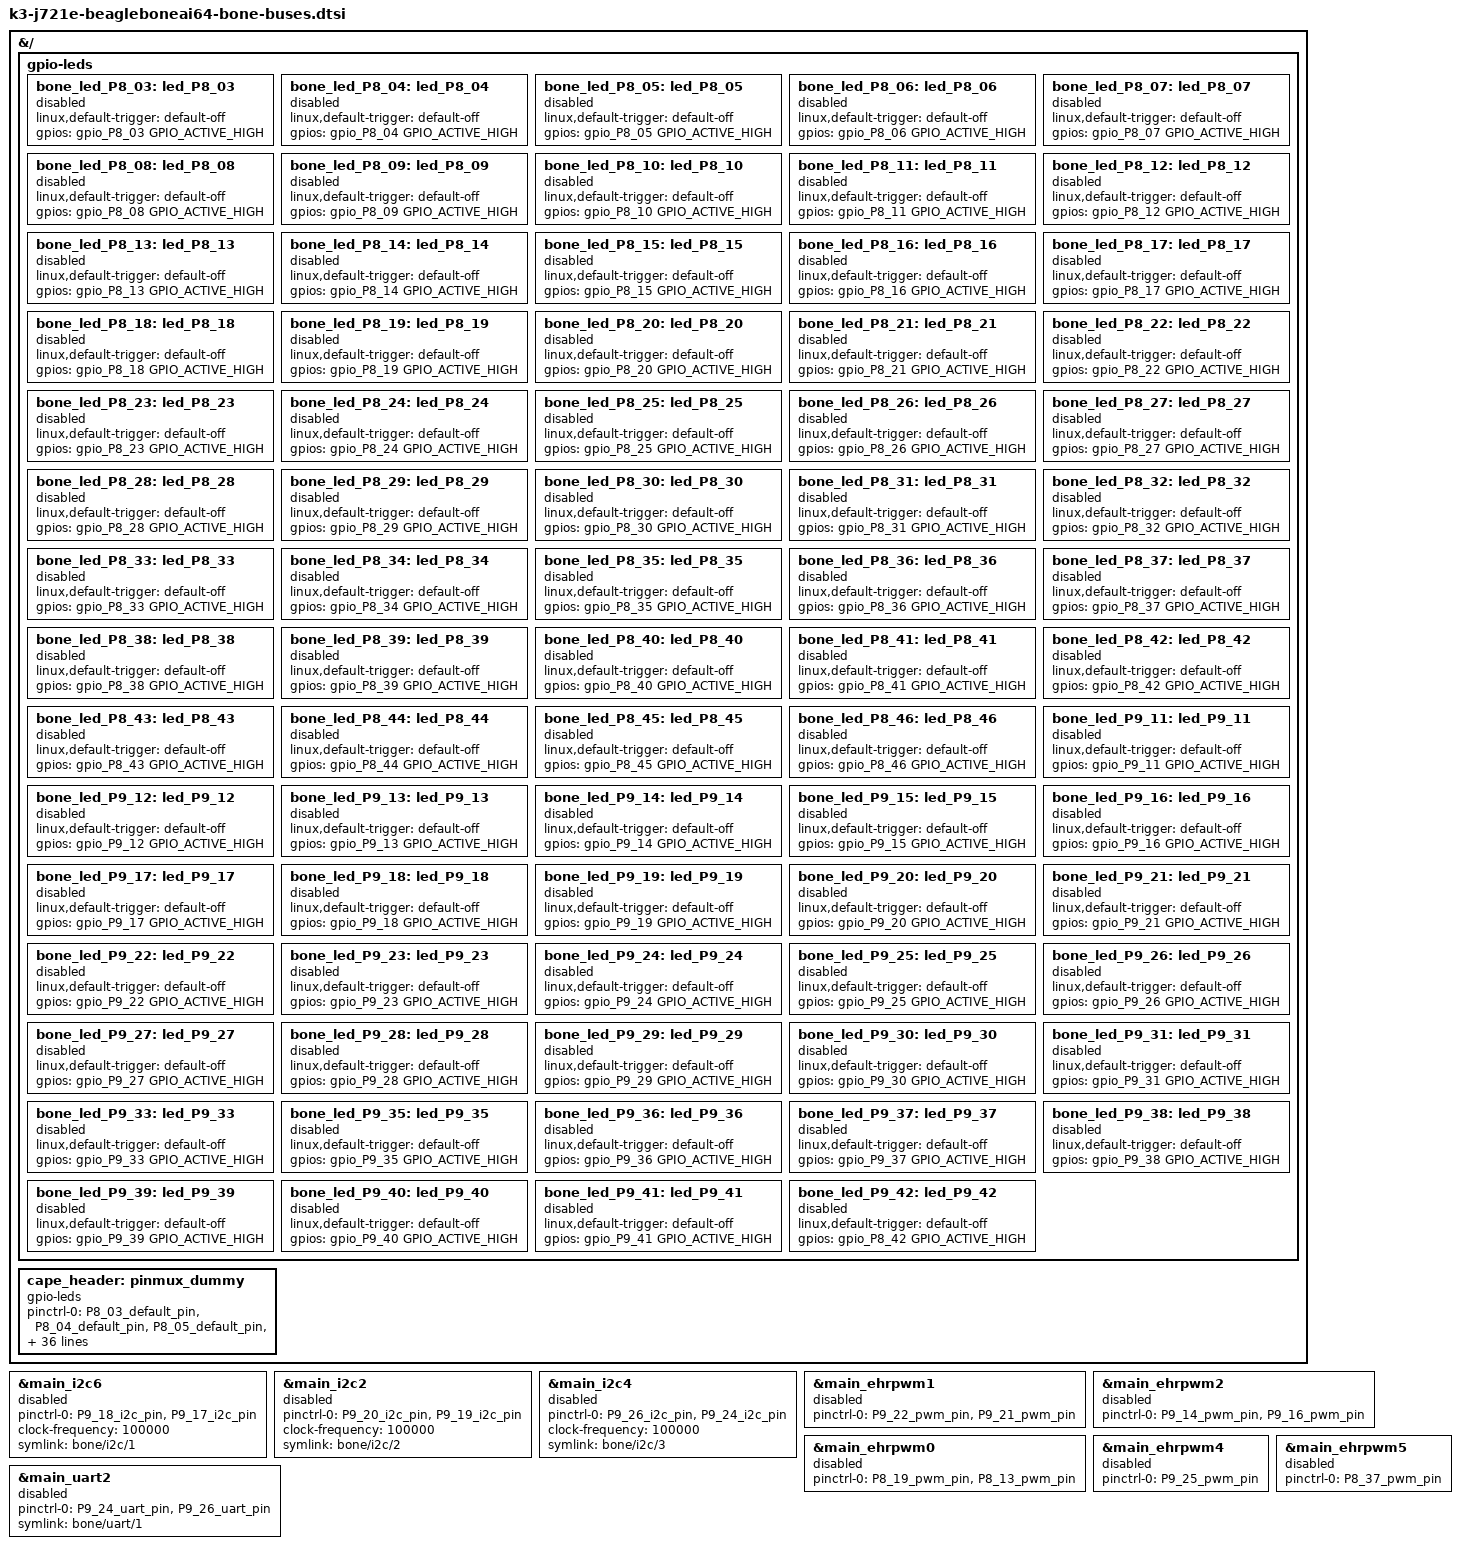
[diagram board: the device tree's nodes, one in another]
// SPDX-License-Identifier: GPL-2.0
/*
 * Copyright (C) 2022 BeagleBoard.org - https://beagleboard.org/
 */

#include <dt-bindings/gpio/gpio.h>
#include <dt-bindings/board/k3-j721e-bone-pins.h>

/********/
/* LEDs */
/********/
&{/} {
	gpio-leds {
		bone_led_P8_03: led_P8_03 {
			status = "disabled";
			linux,default-trigger = "default-off";
			gpios = <gpio_P8_03 GPIO_ACTIVE_HIGH>;
		};

		bone_led_P8_04: led_P8_04 {
			status = "disabled";
			linux,default-trigger = "default-off";
			gpios = <gpio_P8_04 GPIO_ACTIVE_HIGH>;
		};

		bone_led_P8_05: led_P8_05 {
			status = "disabled";
			linux,default-trigger = "default-off";
			gpios = <gpio_P8_05 GPIO_ACTIVE_HIGH>;
		};

		bone_led_P8_06: led_P8_06 {
			status = "disabled";
			linux,default-trigger = "default-off";
			gpios = <gpio_P8_06 GPIO_ACTIVE_HIGH>;
		};

		bone_led_P8_07: led_P8_07 {
			status = "disabled";
			linux,default-trigger = "default-off";
			gpios = <gpio_P8_07 GPIO_ACTIVE_HIGH>;
		};

		bone_led_P8_08: led_P8_08 {
			status = "disabled";
			linux,default-trigger = "default-off";
			gpios = <gpio_P8_08 GPIO_ACTIVE_HIGH>;
		};

		bone_led_P8_09: led_P8_09 {
			status = "disabled";
			linux,default-trigger = "default-off";
			gpios = <gpio_P8_09 GPIO_ACTIVE_HIGH>;
		};

		bone_led_P8_10: led_P8_10 {
			status = "disabled";
			linux,default-trigger = "default-off";
			gpios = <gpio_P8_10 GPIO_ACTIVE_HIGH>;
		};

		bone_led_P8_11: led_P8_11 {
			status = "disabled";
			linux,default-trigger = "default-off";
			gpios = <gpio_P8_11 GPIO_ACTIVE_HIGH>;
		};

		bone_led_P8_12: led_P8_12 {
			status = "disabled";
			linux,default-trigger = "default-off";
			gpios = <gpio_P8_12 GPIO_ACTIVE_HIGH>;
		};

		bone_led_P8_13: led_P8_13 {
			status = "disabled";
			linux,default-trigger = "default-off";
			gpios = <gpio_P8_13 GPIO_ACTIVE_HIGH>;
		};

		bone_led_P8_14: led_P8_14 {
			status = "disabled";
			linux,default-trigger = "default-off";
			gpios = <gpio_P8_14 GPIO_ACTIVE_HIGH>;
		};

		bone_led_P8_15: led_P8_15 {
			status = "disabled";
			linux,default-trigger = "default-off";
			gpios = <gpio_P8_15 GPIO_ACTIVE_HIGH>;
		};

		bone_led_P8_16: led_P8_16 {
			status = "disabled";
			linux,default-trigger = "default-off";
			gpios = <gpio_P8_16 GPIO_ACTIVE_HIGH>;
		};

		bone_led_P8_17: led_P8_17 {
			status = "disabled";
			linux,default-trigger = "default-off";
			gpios = <gpio_P8_17 GPIO_ACTIVE_HIGH>;
		};

		bone_led_P8_18: led_P8_18 {
			status = "disabled";
			linux,default-trigger = "default-off";
			gpios = <gpio_P8_18 GPIO_ACTIVE_HIGH>;
		};

		bone_led_P8_19: led_P8_19 {
			status = "disabled";
			linux,default-trigger = "default-off";
			gpios = <gpio_P8_19 GPIO_ACTIVE_HIGH>;
		};

		bone_led_P8_20: led_P8_20 {
			status = "disabled";
			linux,default-trigger = "default-off";
			gpios = <gpio_P8_20 GPIO_ACTIVE_HIGH>;
		};

		bone_led_P8_21: led_P8_21 {
			status = "disabled";
			linux,default-trigger = "default-off";
			gpios = <gpio_P8_21 GPIO_ACTIVE_HIGH>;
		};

		bone_led_P8_22: led_P8_22 {
			status = "disabled";
			linux,default-trigger = "default-off";
			gpios = <gpio_P8_22 GPIO_ACTIVE_HIGH>;
		};

		bone_led_P8_23: led_P8_23 {
			status = "disabled";
			linux,default-trigger = "default-off";
			gpios = <gpio_P8_23 GPIO_ACTIVE_HIGH>;
		};

		bone_led_P8_24: led_P8_24 {
			status = "disabled";
			linux,default-trigger = "default-off";
			gpios = <gpio_P8_24 GPIO_ACTIVE_HIGH>;
		};

		bone_led_P8_25: led_P8_25 {
			status = "disabled";
			linux,default-trigger = "default-off";
			gpios = <gpio_P8_25 GPIO_ACTIVE_HIGH>;
		};

		bone_led_P8_26: led_P8_26 {
			status = "disabled";
			linux,default-trigger = "default-off";
			gpios = <gpio_P8_26 GPIO_ACTIVE_HIGH>;
		};

		bone_led_P8_27: led_P8_27 {
			status = "disabled";
			linux,default-trigger = "default-off";
			gpios = <gpio_P8_27 GPIO_ACTIVE_HIGH>;
		};

		bone_led_P8_28: led_P8_28 {
			status = "disabled";
			linux,default-trigger = "default-off";
			gpios = <gpio_P8_28 GPIO_ACTIVE_HIGH>;
		};

		bone_led_P8_29: led_P8_29 {
			status = "disabled";
			linux,default-trigger = "default-off";
			gpios = <gpio_P8_29 GPIO_ACTIVE_HIGH>;
		};

		bone_led_P8_30: led_P8_30 {
			status = "disabled";
			linux,default-trigger = "default-off";
			gpios = <gpio_P8_30 GPIO_ACTIVE_HIGH>;
		};

		bone_led_P8_31: led_P8_31 {
			status = "disabled";
			linux,default-trigger = "default-off";
			gpios = <gpio_P8_31 GPIO_ACTIVE_HIGH>;
		};

		bone_led_P8_32: led_P8_32 {
			status = "disabled";
			linux,default-trigger = "default-off";
			gpios = <gpio_P8_32 GPIO_ACTIVE_HIGH>;
		};

		bone_led_P8_33: led_P8_33 {
			status = "disabled";
			linux,default-trigger = "default-off";
			gpios = <gpio_P8_33 GPIO_ACTIVE_HIGH>;
		};

		bone_led_P8_34: led_P8_34 {
			status = "disabled";
			linux,default-trigger = "default-off";
			gpios = <gpio_P8_34 GPIO_ACTIVE_HIGH>;
		};

		bone_led_P8_35: led_P8_35 {
			status = "disabled";
			linux,default-trigger = "default-off";
			gpios = <gpio_P8_35 GPIO_ACTIVE_HIGH>;
		};

		bone_led_P8_36: led_P8_36 {
			status = "disabled";
			linux,default-trigger = "default-off";
			gpios = <gpio_P8_36 GPIO_ACTIVE_HIGH>;
		};

		bone_led_P8_37: led_P8_37 {
			status = "disabled";
			linux,default-trigger = "default-off";
			gpios = <gpio_P8_37 GPIO_ACTIVE_HIGH>;
		};

		bone_led_P8_38: led_P8_38 {
			status = "disabled";
			linux,default-trigger = "default-off";
			gpios = <gpio_P8_38 GPIO_ACTIVE_HIGH>;
		};

		bone_led_P8_39: led_P8_39 {
			status = "disabled";
			linux,default-trigger = "default-off";
			gpios = <gpio_P8_39 GPIO_ACTIVE_HIGH>;
		};

		bone_led_P8_40: led_P8_40 {
			status = "disabled";
			linux,default-trigger = "default-off";
			gpios = <gpio_P8_40 GPIO_ACTIVE_HIGH>;
		};

		bone_led_P8_41: led_P8_41 {
			status = "disabled";
			linux,default-trigger = "default-off";
			gpios = <gpio_P8_41 GPIO_ACTIVE_HIGH>;
		};

		bone_led_P8_42: led_P8_42 {
			status = "disabled";
			linux,default-trigger = "default-off";
			gpios = <gpio_P8_42 GPIO_ACTIVE_HIGH>;
		};

		bone_led_P8_43: led_P8_43 {
			status = "disabled";
			linux,default-trigger = "default-off";
			gpios = <gpio_P8_43 GPIO_ACTIVE_HIGH>;
		};

		bone_led_P8_44: led_P8_44 {
			status = "disabled";
			linux,default-trigger = "default-off";
			gpios = <gpio_P8_44 GPIO_ACTIVE_HIGH>;
		};

		bone_led_P8_45: led_P8_45 {
			status = "disabled";
			linux,default-trigger = "default-off";
			gpios = <gpio_P8_45 GPIO_ACTIVE_HIGH>;
		};

		bone_led_P8_46: led_P8_46 {
			status = "disabled";
			linux,default-trigger = "default-off";
			gpios = <gpio_P8_46 GPIO_ACTIVE_HIGH>;
		};

		bone_led_P9_11: led_P9_11 {
			status = "disabled";
			linux,default-trigger = "default-off";
			gpios = <gpio_P9_11 GPIO_ACTIVE_HIGH>;
		};

		bone_led_P9_12: led_P9_12 {
			status = "disabled";
			linux,default-trigger = "default-off";
			gpios = <gpio_P9_12 GPIO_ACTIVE_HIGH>;
		};

		bone_led_P9_13: led_P9_13 {
			status = "disabled";
			linux,default-trigger = "default-off";
			gpios = <gpio_P9_13 GPIO_ACTIVE_HIGH>;
		};

		bone_led_P9_14: led_P9_14 {
			status = "disabled";
			linux,default-trigger = "default-off";
			gpios = <gpio_P9_14 GPIO_ACTIVE_HIGH>;
		};

		bone_led_P9_15: led_P9_15 {
			status = "disabled";
			linux,default-trigger = "default-off";
			gpios = <gpio_P9_15 GPIO_ACTIVE_HIGH>;
		};

		bone_led_P9_16: led_P9_16 {
			status = "disabled";
			linux,default-trigger = "default-off";
			gpios = <gpio_P9_16 GPIO_ACTIVE_HIGH>;
		};

		bone_led_P9_17: led_P9_17 {
			status = "disabled";
			linux,default-trigger = "default-off";
			gpios = <gpio_P9_17 GPIO_ACTIVE_HIGH>;
		};

		bone_led_P9_18: led_P9_18 {
			status = "disabled";
			linux,default-trigger = "default-off";
			gpios = <gpio_P9_18 GPIO_ACTIVE_HIGH>;
		};

		bone_led_P9_19: led_P9_19 {
			status = "disabled";
			linux,default-trigger = "default-off";
			gpios = <gpio_P9_19 GPIO_ACTIVE_HIGH>;
		};

		bone_led_P9_20: led_P9_20 {
			status = "disabled";
			linux,default-trigger = "default-off";
			gpios = <gpio_P9_20 GPIO_ACTIVE_HIGH>;
		};

		bone_led_P9_21: led_P9_21 {
			status = "disabled";
			linux,default-trigger = "default-off";
			gpios = <gpio_P9_21 GPIO_ACTIVE_HIGH>;
		};

		bone_led_P9_22: led_P9_22 {
			status = "disabled";
			linux,default-trigger = "default-off";
			gpios = <gpio_P9_22 GPIO_ACTIVE_HIGH>;
		};

		bone_led_P9_23: led_P9_23 {
			status = "disabled";
			linux,default-trigger = "default-off";
			gpios = <gpio_P9_23 GPIO_ACTIVE_HIGH>;
		};

		bone_led_P9_24: led_P9_24 {
			status = "disabled";
			linux,default-trigger = "default-off";
			gpios = <gpio_P9_24 GPIO_ACTIVE_HIGH>;
		};

		bone_led_P9_25: led_P9_25 {
			status = "disabled";
			linux,default-trigger = "default-off";
			gpios = <gpio_P9_25 GPIO_ACTIVE_HIGH>;
		};

		bone_led_P9_26: led_P9_26 {
			status = "disabled";
			linux,default-trigger = "default-off";
			gpios = <gpio_P9_26 GPIO_ACTIVE_HIGH>;
		};

		bone_led_P9_27: led_P9_27 {
			status = "disabled";
			linux,default-trigger = "default-off";
			gpios = <gpio_P9_27 GPIO_ACTIVE_HIGH>;
		};

		bone_led_P9_28: led_P9_28 {
			status = "disabled";
			linux,default-trigger = "default-off";
			gpios = <gpio_P9_28 GPIO_ACTIVE_HIGH>;
		};

		bone_led_P9_29: led_P9_29 {
			status = "disabled";
			linux,default-trigger = "default-off";
			gpios = <gpio_P9_29 GPIO_ACTIVE_HIGH>;
		};

		bone_led_P9_30: led_P9_30 {
			status = "disabled";
			linux,default-trigger = "default-off";
			gpios = <gpio_P9_30 GPIO_ACTIVE_HIGH>;
		};

		bone_led_P9_31: led_P9_31 {
			status = "disabled";
			linux,default-trigger = "default-off";
			gpios = <gpio_P9_31 GPIO_ACTIVE_HIGH>;
		};

		bone_led_P9_33: led_P9_33 {
			status = "disabled";
			linux,default-trigger = "default-off";
			gpios = <gpio_P9_33 GPIO_ACTIVE_HIGH>;
		};

		bone_led_P9_35: led_P9_35 {
			status = "disabled";
			linux,default-trigger = "default-off";
			gpios = <gpio_P9_35 GPIO_ACTIVE_HIGH>;
		};

		bone_led_P9_36: led_P9_36 {
			status = "disabled";
			linux,default-trigger = "default-off";
			gpios = <gpio_P9_36 GPIO_ACTIVE_HIGH>;
		};

		bone_led_P9_37: led_P9_37 {
			status = "disabled";
			linux,default-trigger = "default-off";
			gpios = <gpio_P9_37 GPIO_ACTIVE_HIGH>;
		};

		bone_led_P9_38: led_P9_38 {
			status = "disabled";
			linux,default-trigger = "default-off";
			gpios = <gpio_P9_38 GPIO_ACTIVE_HIGH>;
		};

		bone_led_P9_39: led_P9_39 {
			status = "disabled";
			linux,default-trigger = "default-off";
			gpios = <gpio_P9_39 GPIO_ACTIVE_HIGH>;
		};

		bone_led_P9_40: led_P9_40 {
			status = "disabled";
			linux,default-trigger = "default-off";
			gpios = <gpio_P9_40 GPIO_ACTIVE_HIGH>;
		};

		bone_led_P9_41: led_P9_41 {
			status = "disabled";
			linux,default-trigger = "default-off";
			gpios = <gpio_P9_41 GPIO_ACTIVE_HIGH>;
		};

		bone_led_P9_42: led_P9_42 {
			status = "disabled";
			linux,default-trigger = "default-off";
			gpios = <gpio_P8_42 GPIO_ACTIVE_HIGH>;
		};
	};

	/* Dummy driver to request setup for cape header pins */
	cape_header: pinmux_dummy {
		compatible = "gpio-leds";
		pinctrl-names = "default";
		pinctrl-0 = <
			&P8_03_default_pin
			&P8_04_default_pin
			&P8_05_default_pin
			&P8_06_default_pin
			&P8_07_default_pin
			&P8_08_default_pin
			&P8_09_default_pin
			&P8_10_default_pin
			&P8_11_default_pin
			&P8_12_default_pin
			&P8_13_default_pin
			&P8_14_default_pin
			&P8_15_default_pin
			&P8_16_default_pin
			&P8_17_default_pin
			&P8_18_default_pin
			&P8_19_default_pin
			&P8_20_default_pin
			&P8_21_default_pin
			&P8_22_default_pin
			&P8_23_default_pin
			&P8_24_default_pin
			&P8_25_default_pin
			&P8_26_default_pin
			&P8_27_default_pin
			&P8_28_default_pin
			&P8_29_default_pin
			&P8_30_default_pin
			&P8_31_default_pin
			&P8_32_default_pin
			&P8_33_default_pin
			&P8_34_default_pin
			&P8_35_default_pin
			&P8_36_default_pin
			&P8_37_default_pin
			&P8_38_default_pin
			&P8_39_default_pin
			&P8_40_default_pin
			&P8_41_default_pin
			&P8_42_default_pin
			&P8_43_default_pin
			&P8_44_default_pin
			&P8_45_default_pin
			&P8_46_default_pin
			&P9_11_default_pin
			&P9_12_default_pin
			&P9_13_default_pin
			&P9_14_default_pin
			&P9_15_default_pin
			&P9_16_default_pin
			&P9_17_default_pin
			&P9_18_default_pin
			&P9_19_default_pin
			&P9_20_default_pin
			&P9_21_default_pin
			&P9_22_default_pin
			&P9_23_default_pin
			&P9_24_default_pin
			&P9_25_default_pin
			&P9_26_default_pin
			&P9_27_default_pin
			&P9_28_default_pin
			&P9_29_default_pin
			&P9_30_default_pin
			&P9_31_default_pin
			&P9_33_default_pin
			&P9_35_default_pin
			&P9_36_default_pin
			&P9_37_default_pin
			&P9_38_default_pin
			&P9_39_default_pin
			&P9_40_default_pin
			&P9_41_default_pin
			&P9_42_default_pin
		>;
	};
};

bone_i2c_1: &main_i2c6 {
	pinctrl-names = "default";
	pinctrl-0 = <
		&P9_18_i2c_pin /* i2c6_sda */
		&P9_17_i2c_pin /* i2c6_scl */
	>;
	clock-frequency = <100000>;

	symlink = "bone/i2c/1";
	status = "disabled";
};

bone_i2c_2: &main_i2c2 {
	pinctrl-names = "default";
	pinctrl-0 = <
		&P9_20_i2c_pin /* i2c2_sda */
		&P9_19_i2c_pin /* i2c2_scl */
	>;
	clock-frequency = <100000>;

	symlink = "bone/i2c/2";
	status = "disabled";
};

bone_i2c_3: &main_i2c4 {
	pinctrl-names = "default";
	pinctrl-0 = <
		&P9_26_i2c_pin /* i2c4_sda */
		&P9_24_i2c_pin /* i2c4_scl */
	>;
	clock-frequency = <100000>;

	symlink = "bone/i2c/3";
	status = "disabled";
};

bone_pwm_0: &main_ehrpwm1 {
	// location: /dev/bone/pwm/0
	pinctrl-names = "default";
	pinctrl-0 = <
		&P9_22_pwm_pin /* PWM A */
		&P9_21_pwm_pin /* PWM B */
	>;
	status = "disabled";
};

bone_pwm_1: &main_ehrpwm2 {
	// location: /dev/bone/pwm/1
	pinctrl-names = "default";
	pinctrl-0 = <
		&P9_14_pwm_pin /* PWM A */
		&P9_16_pwm_pin /* PWM B */
	>;
	status = "disabled";
};

bone_pwm_2: &main_ehrpwm0 {
	// location: /dev/bone/pwm/2
	pinctrl-names = "default";
	pinctrl-0 = <
		&P8_19_pwm_pin /* PWM A */
		&P8_13_pwm_pin /* PWM B */
	>;
	status = "disabled";
};

&main_ehrpwm4 {
	pinctrl-names = "default";
	pinctrl-0 = <
		&P9_25_pwm_pin /* PWM B */
	>;
	status = "disabled";
};

&main_ehrpwm5 {
	pinctrl-names = "default";
	pinctrl-0 = <
		&P8_37_pwm_pin /* PWM A */
	>;
	status = "disabled";
};

bone_uart_1: &main_uart2 {
	pinctrl-names = "default";
	pinctrl-0 = <
		&P9_24_uart_pin /* uart2_txd */
		&P9_26_uart_pin /* uart2_rxd */
	>;
	symlink = "bone/uart/1";
	status = "disabled";
};
